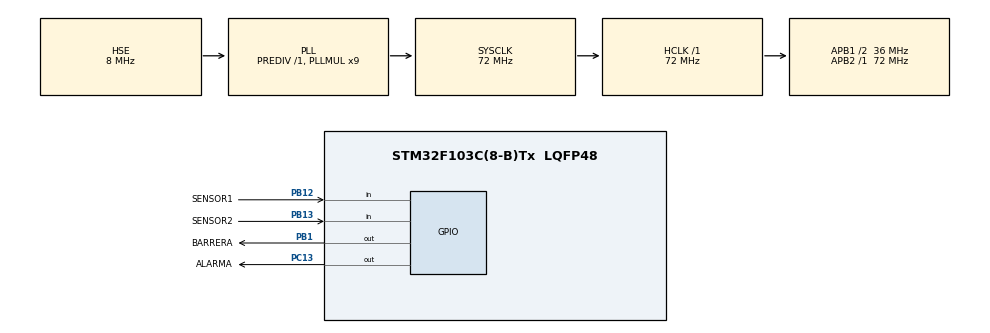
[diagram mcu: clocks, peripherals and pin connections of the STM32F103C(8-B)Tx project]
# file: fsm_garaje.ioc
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Mcu.Family=STM32F1
RCC.PLLSourceVirtual=RCC_PLLSOURCE_HSE
PC15-OSC32_OUT.Mode=LSE-External-Oscillator
PD1-OSC_OUT.Mode=HSE-External-Oscillator
PC13-TAMPER-RTC.Signal=GPIO_Output
PD0-OSC_IN.Signal=RCC_OSC_IN
RCC.APB1CLKDivider=RCC_HCLK_DIV2
PC14-OSC32_IN.Signal=RCC_OSC32_IN
PB13.GPIO_Label=SENSOR2
PB13.Signal=GPIO_Input
RCC.SYSCLKSource=RCC_SYSCLKSOURCE_PLLCLK
ProjectManager.StackSize=0x400
PD1-OSC_OUT.Signal=RCC_OSC_OUT
PA13.Signal=SYS_JTMS-SWDIO
ProjectManager.TargetToolchain=STM32CubeIDE
RCC.HCLKFreq_Value=72000000
RCC.APB2TimFreq_Value=72000000
RCC.USBFreq_Value=72000000
PC15-OSC32_OUT.Signal=RCC_OSC32_OUT
RCC.AHBFreq_Value=72000000
PD0-OSC_IN.Mode=HSE-External-Oscillator
board=custom
PC13-TAMPER-RTC.GPIO_Label=ALARMA
RCC.PLLMUL=RCC_PLL_MUL9
PB12.GPIO_Label=SENSOR1
PB13.GPIO_PuPd=GPIO_PULLUP
RCC.APB2Freq_Value=72000000
PC14-OSC32_IN.Mode=LSE-External-Oscillator
PC13-TAMPER-RTC.PinState=GPIO_PIN_SET
PA14.Mode=Serial_Wire
PB1.GPIO_Label=BARRERA
PA13.Mode=Serial_Wire
Mcu.Name=STM32F103C(8-B)Tx
PB1.PinState=GPIO_PIN_SET
RCC.SYSCLKFreq_VALUE=72000000
Mcu.Package=LQFP48
PB1.Signal=GPIO_Output
PA14.Signal=SYS_JTCK-SWCLK
ProjectManager.HeapSize=0x200
NVIC.PriorityGroup=NVIC_PRIORITYGROUP_4
RCC.APB1TimFreq_Value=72000000
PB12.GPIO_PuPd=GPIO_PULLUP
RCC.APB1Freq_Value=36000000
PB12.Signal=GPIO_Input

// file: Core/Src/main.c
/* USER CODE BEGIN Header */
/**
 ******************************************************************************
 * @file           : main.c
 * @brief          : Main program body
 ******************************************************************************
 * @attention
 *
 * <h2><center>&copy; Copyright (c) 2021 STMicroelectronics.
 * All rights reserved.</center></h2>
 *
 * This software component is licensed by ST under BSD 3-Clause license,
 * the "License"; You may not use this file except in compliance with the
 * License. You may obtain a copy of the License at:
 *                        opensource.org/licenses/BSD-3-Clause
 *
 ******************************************************************************
 * @mainpage Sistema de acceso a un garaje
 *
 * El sistema cuenta con:
 * - Una barrera vehicular eléctrica
 * - Dos sensores que detectan la presencia de un vehículo
 * - Un buzzer en caso de alarma
 *
 * El comportamiento del sistema es el siguiente:
 * -# Si se detecta que un vehículo quiere ingresar (sensor 1) se abre la
 *    barrera
 * -# Una vez que el vehículo cruza la barrera (sensor 2), la misma se debe
 *    mantener elevada por 5 segundos.
 * -# Si en ese momento se detecta que otro vehículo quiere ingresar (sensor 1),
 *    la barrera se debe mantener elevada hasta que el mismo la cruza (sensor
 *    2), y la cuenta de los 5 segundos se debe reiniciar.
 * -# Si el sensor 2 se activa con la barrera baja, no se debe permitir la
 *    activación de la barrera y debe sonar el buzzer de alarma.
 */
/* USER CODE END Header */
#include "main.h"

/* USER CODE BEGIN Includes */
#include "fsm_garaje.h"
#include "user_gpio.h"
/* USER CODE END Includes */

void SystemClock_Config(void);
static void MX_GPIO_Init(void);

/* USER CODE BEGIN 0 */

/**
 * @brief  This function is called by the SysTick interrupt handler every
 *         1 ms by default.
 * @note   This implementation overrides the existing weak function in
 *         stm32f1xx_hal.c file.
 * @retval None
 */
void HAL_IncTick(void)
{
	uwTick += uwTickFreq;
	fsm_garaje_tick();
}

/* USER CODE END 0 */

int main(void)
{

	/* MCU Configuration--------------------------------------------------------*/

	/* Reset of all peripherals, Initializes the Flash interface and the Systick. */
	HAL_Init();

	/* Configure the system clock */
	SystemClock_Config();

	/* Initialize all configured peripherals */
	MX_GPIO_Init();
	/* USER CODE BEGIN 2 */
	user_gpio_init();
	fsm_garaje_init();
	/* USER CODE END 2 */

	/* Infinite loop */
	/* USER CODE BEGIN WHILE */
	while (1)
	{
		user_gpio_loop();
		fsm_garaje_runCycle();

		__WFI();

		/* USER CODE END WHILE */

	}
}

void SystemClock_Config(void)
{
	RCC_OscInitTypeDef RCC_OscInitStruct = {0};
	RCC_ClkInitTypeDef RCC_ClkInitStruct = {0};

	/** Initializes the RCC Oscillators according to the specified parameters
	 * in the RCC_OscInitTypeDef structure.
	 */
	RCC_OscInitStruct.OscillatorType = RCC_OSCILLATORTYPE_HSE;
	RCC_OscInitStruct.HSEState = RCC_HSE_ON;
	RCC_OscInitStruct.HSEPredivValue = RCC_HSE_PREDIV_DIV1;
	RCC_OscInitStruct.HSIState = RCC_HSI_ON;
	RCC_OscInitStruct.PLL.PLLState = RCC_PLL_ON;
	RCC_OscInitStruct.PLL.PLLSource = RCC_PLLSOURCE_HSE;
	RCC_OscInitStruct.PLL.PLLMUL = RCC_PLL_MUL9;
	if (HAL_RCC_OscConfig(&RCC_OscInitStruct) != HAL_OK)
	{
		Error_Handler();
	}
	/** Initializes the CPU, AHB and APB buses clocks
	 */
	RCC_ClkInitStruct.ClockType = RCC_CLOCKTYPE_HCLK|RCC_CLOCKTYPE_SYSCLK
			|RCC_CLOCKTYPE_PCLK1|RCC_CLOCKTYPE_PCLK2;
	RCC_ClkInitStruct.SYSCLKSource = RCC_SYSCLKSOURCE_PLLCLK;
	RCC_ClkInitStruct.AHBCLKDivider = RCC_SYSCLK_DIV1;
	RCC_ClkInitStruct.APB1CLKDivider = RCC_HCLK_DIV2;
	RCC_ClkInitStruct.APB2CLKDivider = RCC_HCLK_DIV1;

	if (HAL_RCC_ClockConfig(&RCC_ClkInitStruct, FLASH_LATENCY_2) != HAL_OK)
	{
		Error_Handler();
	}
}

static void MX_GPIO_Init(void)
{
	GPIO_InitTypeDef GPIO_InitStruct = {0};

	/* GPIO Ports Clock Enable */
	__HAL_RCC_GPIOC_CLK_ENABLE();
	__HAL_RCC_GPIOD_CLK_ENABLE();
	__HAL_RCC_GPIOB_CLK_ENABLE();
	__HAL_RCC_GPIOA_CLK_ENABLE();

	/*Configure GPIO pin Output Level */
	HAL_GPIO_WritePin(ALARMA_GPIO_Port, ALARMA_Pin, GPIO_PIN_SET);

	/*Configure GPIO pin Output Level */
	HAL_GPIO_WritePin(BARRERA_GPIO_Port, BARRERA_Pin, GPIO_PIN_SET);

	/*Configure GPIO pin : ALARMA_Pin */
	GPIO_InitStruct.Pin = ALARMA_Pin;
	GPIO_InitStruct.Mode = GPIO_MODE_OUTPUT_PP;
	GPIO_InitStruct.Pull = GPIO_NOPULL;
	GPIO_InitStruct.Speed = GPIO_SPEED_FREQ_LOW;
	HAL_GPIO_Init(ALARMA_GPIO_Port, &GPIO_InitStruct);

	/*Configure GPIO pin : BARRERA_Pin */
	GPIO_InitStruct.Pin = BARRERA_Pin;
	GPIO_InitStruct.Mode = GPIO_MODE_OUTPUT_PP;
	GPIO_InitStruct.Pull = GPIO_NOPULL;
	GPIO_InitStruct.Speed = GPIO_SPEED_FREQ_LOW;
	HAL_GPIO_Init(BARRERA_GPIO_Port, &GPIO_InitStruct);

	/*Configure GPIO pins : SENSOR1_Pin SENSOR2_Pin */
	GPIO_InitStruct.Pin = SENSOR1_Pin|SENSOR2_Pin;
	GPIO_InitStruct.Mode = GPIO_MODE_INPUT;
	GPIO_InitStruct.Pull = GPIO_PULLUP;
	HAL_GPIO_Init(GPIOB, &GPIO_InitStruct);

}

void Error_Handler(void)
{
	__disable_irq();
	while (1)
	{
	}
}

/************************ (C) COPYRIGHT STMicroelectronics *****END OF FILE****/
